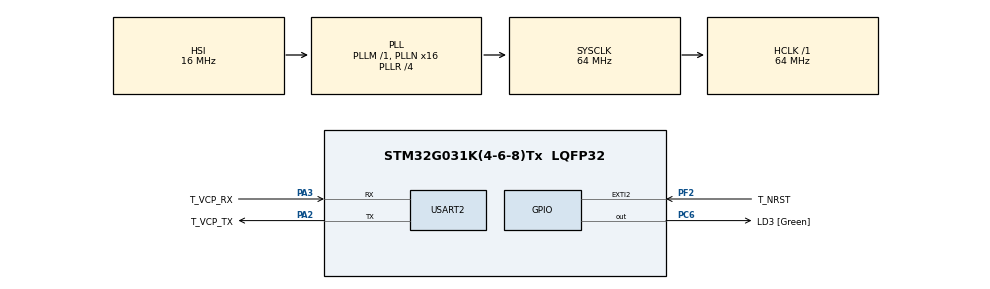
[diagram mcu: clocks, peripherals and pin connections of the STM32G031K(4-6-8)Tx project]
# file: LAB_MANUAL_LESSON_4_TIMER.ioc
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Mcu.Family=STM32G0
Mcu.Name=STM32G031K(4-6-8)Tx
Mcu.Package=LQFP32
NVIC.TIM1_BRK_UP_TRG_COM_IRQn=true\:1\:0\:true\:false\:true\:true\:true
NVIC.TIM1_CC_IRQn=true\:1\:0\:true\:false\:true\:true\:true
PA13.GPIO_Label=T_JTMS
PA13.Mode=Serial_Wire
PA13.Signal=SYS_SWDIO
PA14-BOOT0.GPIO_Label=T_JTCK
PA14-BOOT0.Mode=Serial_Wire
PA14-BOOT0.Signal=SYS_SWCLK
PA2.GPIO_Label=T_VCP_TX
PA2.Mode=Asynchronous
PA2.Signal=USART2_TX
PA3.GPIO_Label=T_VCP_RX
PA3.Mode=Asynchronous
PA3.Signal=USART2_RX
PC14-OSC32_IN\ (PC14).Mode=LSE-External-Oscillator
PC14-OSC32_IN\ (PC14).Signal=RCC_OSC32_IN
PC15-OSC32_OUT\ (PC15).Mode=LSE-External-Oscillator
PC15-OSC32_OUT\ (PC15).Signal=RCC_OSC32_OUT
PC6.GPIO_Label=LD3 [Green]
PC6.Signal=GPIO_Output
PF2\ -\ NRST.GPIO_Label=T_NRST
PF2\ -\ NRST.Signal=GPXTI2
ProjectManager.HeapSize=0x200
ProjectManager.StackSize=0x400
ProjectManager.TargetToolchain=MDK-ARM V5
RCC.ADCFreq_Value=64000000
RCC.AHBFreq_Value=64000000
RCC.APB1CLKDivider=RCC_HCLK_DIV2
RCC.CortexFreq_Value=64000000
RCC.EXTERNAL_CLOCK_VALUE=12288000
RCC.HCLKFreq_Value=64000000
RCC.HSE_VALUE=8000000
RCC.HSI_VALUE=16000000
RCC.PLLN=16
RCC.PLLR=RCC_PLLR_DIV4
RCC.SYSCLKFreq_VALUE=64000000
RCC.SYSCLKSource=RCC_SYSCLKSOURCE_PLLCLK
RCC.TIM1CLockSelectionVirtual=RCC_TIM1CLKSOURCE_PLL
RCC.VCOOutputFreq_Value=256000000
TIM1.Period=2000-1
TIM1.Prescaler=64000-1
USART2.VirtualMode-Asynchronous=VM_ASYNC
USART2.WordLength=WORDLENGTH_8B
VP_TIM1_VS_ClockSourceINT.Mode=Internal
board=NUCLEO-G031K8

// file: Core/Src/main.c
/* USER CODE BEGIN Header */
/**
  ******************************************************************************
  * @file           : main.c
  * @brief          : Main program body
  ******************************************************************************
  * @attention
  *
  * <h2><center>&copy; Copyright (c) 2019 STMicroelectronics.
  * All rights reserved.</center></h2>
  *
  * This software component is licensed by ST under BSD 3-Clause license,
  * the "License"; You may not use this file except in compliance with the
  * License. You may obtain a copy of the License at:
  *                        opensource.org/licenses/BSD-3-Clause
  *
  ******************************************************************************
  */
/* USER CODE END Header */

#include "main.h"
#include "tim.h"
#include "usart.h"
#include "gpio.h"

/* USER CODE BEGIN PV */
extern TIM_HandleTypeDef htim1;
/* USER CODE END PV */

void SystemClock_Config(void);

int main(void)
{

  /* MCU Configuration--------------------------------------------------------*/

  /* Reset of all peripherals, Initializes the Flash interface and the Systick. */
  HAL_Init();

  /* Configure the system clock */
  SystemClock_Config();

  /* Initialize all configured peripherals */
  MX_GPIO_Init();
  MX_USART2_UART_Init();
  MX_TIM1_Init();
  /* USER CODE BEGIN 2 */
	PRINTF("This is TEST for Timer\r\n");
	HAL_TIM_Base_Start_IT(&htim1);
  /* USER CODE END 2 */

  /* Infinite loop */
  while (1)
  {

  }
}

void SystemClock_Config(void)
{
  RCC_OscInitTypeDef RCC_OscInitStruct = {0};
  RCC_ClkInitTypeDef RCC_ClkInitStruct = {0};
  RCC_PeriphCLKInitTypeDef PeriphClkInit = {0};

  /** Configure the main internal regulator output voltage
  */
  HAL_PWREx_ControlVoltageScaling(PWR_REGULATOR_VOLTAGE_SCALE1);
  /** Initializes the CPU, AHB and APB busses clocks
  */
  RCC_OscInitStruct.OscillatorType = RCC_OSCILLATORTYPE_HSI;
  RCC_OscInitStruct.HSIState = RCC_HSI_ON;
  RCC_OscInitStruct.HSIDiv = RCC_HSI_DIV1;
  RCC_OscInitStruct.HSICalibrationValue = RCC_HSICALIBRATION_DEFAULT;
  RCC_OscInitStruct.PLL.PLLState = RCC_PLL_ON;
  RCC_OscInitStruct.PLL.PLLSource = RCC_PLLSOURCE_HSI;
  RCC_OscInitStruct.PLL.PLLM = RCC_PLLM_DIV1;
  RCC_OscInitStruct.PLL.PLLN = 16;
  RCC_OscInitStruct.PLL.PLLP = RCC_PLLP_DIV2;
  RCC_OscInitStruct.PLL.PLLQ = RCC_PLLQ_DIV2;
  RCC_OscInitStruct.PLL.PLLR = RCC_PLLR_DIV4;
  if (HAL_RCC_OscConfig(&RCC_OscInitStruct) != HAL_OK)
  {
    Error_Handler();
  }
  /** Initializes the CPU, AHB and APB busses clocks
  */
  RCC_ClkInitStruct.ClockType = RCC_CLOCKTYPE_HCLK|RCC_CLOCKTYPE_SYSCLK
                              |RCC_CLOCKTYPE_PCLK1;
  RCC_ClkInitStruct.SYSCLKSource = RCC_SYSCLKSOURCE_PLLCLK;
  RCC_ClkInitStruct.AHBCLKDivider = RCC_SYSCLK_DIV1;
  RCC_ClkInitStruct.APB1CLKDivider = RCC_HCLK_DIV2;

  if (HAL_RCC_ClockConfig(&RCC_ClkInitStruct, FLASH_LATENCY_2) != HAL_OK)
  {
    Error_Handler();
  }
  /** Initializes the peripherals clocks
  */
  PeriphClkInit.PeriphClockSelection = RCC_PERIPHCLK_TIM1;
  PeriphClkInit.Tim1ClockSelection = RCC_TIM1CLKSOURCE_PLL;
  if (HAL_RCCEx_PeriphCLKConfig(&PeriphClkInit) != HAL_OK)
  {
    Error_Handler();
  }
}

/* USER CODE BEGIN 4 */
void HAL_TIM_PeriodElapsedCallback(TIM_HandleTypeDef *htim)
{
	if(htim->Instance == TIM1)
	{
		HAL_GPIO_TogglePin(LD3_GPIO_Port, LD3_Pin);
		PRINTF("This is 1s\r\n");
	}
}
/* USER CODE END 4 */

void Error_Handler(void)
{
  /* USER CODE BEGIN Error_Handler_Debug */
  /* User can add his own implementation to report the HAL error return state */
	while(1);
  /* USER CODE END Error_Handler_Debug */
}

/************************ (C) COPYRIGHT STMicroelectronics *****END OF FILE****/
